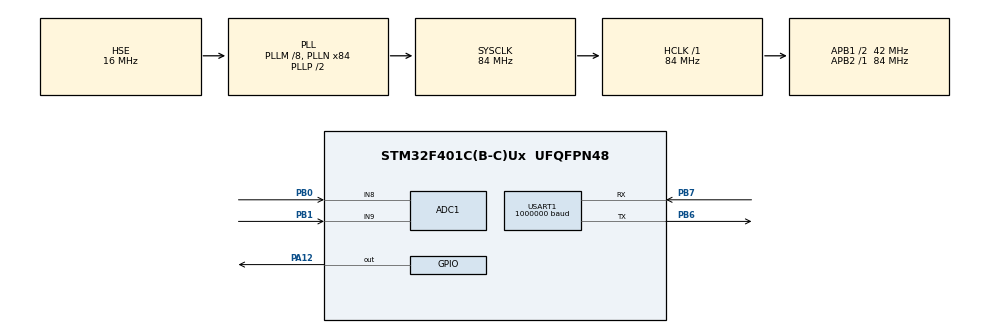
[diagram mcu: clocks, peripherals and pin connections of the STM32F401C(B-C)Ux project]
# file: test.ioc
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ADC1.Channel-0\#ChannelRegularConversion=ADC_CHANNEL_8
ADC1.Channel-1\#ChannelRegularConversion=ADC_CHANNEL_9
ADC1.ContinuousConvMode=ENABLE
ADC1.DMAContinuousRequests=ENABLE
ADC1.NbrOfConversion=2
ADC1.NbrOfConversionFlag=1
ADC1.Rank-0\#ChannelRegularConversion=1
ADC1.Rank-1\#ChannelRegularConversion=2
ADC1.SamplingTime-0\#ChannelRegularConversion=ADC_SAMPLETIME_56CYCLES
ADC1.SamplingTime-1\#ChannelRegularConversion=ADC_SAMPLETIME_56CYCLES
ADC1.ScanConvMode=ENABLE
ADC1.master=1
Dma.ADC1.2.Direction=DMA_PERIPH_TO_MEMORY
Dma.ADC1.2.FIFOMode=DMA_FIFOMODE_ENABLE
Dma.ADC1.2.FIFOThreshold=DMA_FIFO_THRESHOLD_FULL
Dma.ADC1.2.Instance=DMA2_Stream0
Dma.ADC1.2.MemBurst=DMA_MBURST_SINGLE
Dma.ADC1.2.MemDataAlignment=DMA_MDATAALIGN_HALFWORD
Dma.ADC1.2.MemInc=DMA_MINC_ENABLE
Dma.ADC1.2.Mode=DMA_CIRCULAR
Dma.ADC1.2.PeriphBurst=DMA_PBURST_SINGLE
Dma.ADC1.2.PeriphDataAlignment=DMA_PDATAALIGN_HALFWORD
Dma.ADC1.2.PeriphInc=DMA_PINC_DISABLE
Dma.ADC1.2.Priority=DMA_PRIORITY_LOW
Dma.Request0=USART1_RX
Dma.Request1=USART1_TX
Dma.Request2=ADC1
Dma.USART1_RX.0.Direction=DMA_PERIPH_TO_MEMORY
Dma.USART1_RX.0.FIFOMode=DMA_FIFOMODE_ENABLE
Dma.USART1_RX.0.FIFOThreshold=DMA_FIFO_THRESHOLD_FULL
Dma.USART1_RX.0.Instance=DMA2_Stream2
Dma.USART1_RX.0.MemBurst=DMA_MBURST_SINGLE
Dma.USART1_RX.0.MemDataAlignment=DMA_MDATAALIGN_BYTE
Dma.USART1_RX.0.MemInc=DMA_MINC_ENABLE
Dma.USART1_RX.0.Mode=DMA_NORMAL
Dma.USART1_RX.0.PeriphBurst=DMA_PBURST_SINGLE
Dma.USART1_RX.0.PeriphDataAlignment=DMA_PDATAALIGN_BYTE
Dma.USART1_RX.0.PeriphInc=DMA_PINC_DISABLE
Dma.USART1_RX.0.Priority=DMA_PRIORITY_LOW
Dma.USART1_TX.1.Direction=DMA_MEMORY_TO_PERIPH
Dma.USART1_TX.1.FIFOMode=DMA_FIFOMODE_ENABLE
Dma.USART1_TX.1.FIFOThreshold=DMA_FIFO_THRESHOLD_FULL
Dma.USART1_TX.1.Instance=DMA2_Stream7
Dma.USART1_TX.1.MemBurst=DMA_MBURST_SINGLE
Dma.USART1_TX.1.MemDataAlignment=DMA_MDATAALIGN_BYTE
Dma.USART1_TX.1.MemInc=DMA_MINC_ENABLE
Dma.USART1_TX.1.Mode=DMA_NORMAL
Dma.USART1_TX.1.PeriphBurst=DMA_PBURST_SINGLE
Dma.USART1_TX.1.PeriphDataAlignment=DMA_PDATAALIGN_BYTE
Dma.USART1_TX.1.PeriphInc=DMA_PINC_DISABLE
Dma.USART1_TX.1.Priority=DMA_PRIORITY_LOW
Mcu.Family=STM32F4
Mcu.Name=STM32F401C(B-C)Ux
Mcu.Package=UFQFPN48
NVIC.ADC_IRQn=true\:0\:0\:false\:false\:true\:true\:true\:true
NVIC.DMA2_Stream0_IRQn=true\:0\:0\:false\:false\:true\:false\:true\:true
NVIC.DMA2_Stream2_IRQn=true\:0\:0\:false\:false\:true\:false\:true\:true
NVIC.DMA2_Stream7_IRQn=true\:0\:0\:false\:false\:true\:false\:true\:true
NVIC.PriorityGroup=NVIC_PRIORITYGROUP_4
NVIC.TIM2_IRQn=true\:0\:0\:true\:false\:true\:true\:true\:true
NVIC.TIM5_IRQn=true\:0\:0\:true\:false\:true\:true\:true\:true
NVIC.USART1_IRQn=true\:0\:0\:false\:false\:true\:true\:true\:true
PA12.Signal=GPIO_Output
PA13.Mode=Serial_Wire
PA13.Signal=SYS_JTMS-SWDIO
PA14.Mode=Serial_Wire
PA14.Signal=SYS_JTCK-SWCLK
PB0.Signal=ADCx_IN8
PB1.Signal=ADCx_IN9
PB6.Mode=Asynchronous
PB6.Signal=USART1_TX
PB7.Mode=Asynchronous
PB7.Signal=USART1_RX
PH0\ -\ OSC_IN.Mode=HSE-External-Oscillator
PH0\ -\ OSC_IN.Signal=RCC_OSC_IN
PH1\ -\ OSC_OUT.Mode=HSE-External-Oscillator
PH1\ -\ OSC_OUT.Signal=RCC_OSC_OUT
ProjectManager.HeapSize=0x2000
ProjectManager.StackSize=0x4000
ProjectManager.TargetToolchain=STM32CubeIDE
RCC.48MHZClocksFreq_Value=42000000
RCC.AHBFreq_Value=84000000
RCC.APB1CLKDivider=RCC_HCLK_DIV2
RCC.APB1Freq_Value=42000000
RCC.APB1TimFreq_Value=84000000
RCC.APB2Freq_Value=84000000
RCC.APB2TimFreq_Value=84000000
RCC.CortexFreq_Value=84000000
RCC.HCLKFreq_Value=84000000
RCC.HSE_VALUE=16000000
RCC.HSI_VALUE=16000000
RCC.LSE_VALUE=32768
RCC.PLLM=8
RCC.PLLN=84
RCC.PLLSourceVirtual=RCC_PLLSOURCE_HSE
RCC.SYSCLKFreq_VALUE=84000000
RCC.SYSCLKSource=RCC_SYSCLKSOURCE_PLLCLK
RCC.VCOOutputFreq_Value=168000000
SH.ADCx_IN8.0=ADC1_IN8,IN8
SH.ADCx_IN9.0=ADC1_IN9,IN9
STMicroelectronics.X-CUBE-ALGOBUILD.1.4.0.LibraryCcDSPOoLibraryJjDSPOoLibrary=true
TIM2.Period=99
TIM2.Prescaler=83
TIM5.Period=999
TIM5.Prescaler=83
USART1.BaudRate=1000000
USART1.VirtualMode=VM_ASYNC
VP_STMicroelectronics.X-CUBE-ALGOBUILD_VS_DSPOoLibraryJjLibrary_1.4.0_1.4.0.Mode=DSPOoLibraryJjLibrary
VP_TIM2_VS_ClockSourceINT.Mode=Internal
VP_TIM5_VS_ClockSourceINT.Mode=Internal
board=custom

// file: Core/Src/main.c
/* USER CODE BEGIN Header */
/**
  ******************************************************************************
  * @file           : main.c
  * @brief          : Main program body
  ******************************************************************************
  * @attention
  *
  * Copyright (c) 2024 STMicroelectronics.
  * All rights reserved.
  *
  * This software is licensed under terms that can be found in the LICENSE file
  * in the root directory of this software component.
  * If no LICENSE file comes with this software, it is provided AS-IS.
  *
  ******************************************************************************
  */
/* USER CODE END Header */
#include "main.h"
#include "adc.h"
#include "dma.h"
#include "tim.h"
#include "usart.h"
#include "gpio.h"

/* USER CODE BEGIN Includes */

#include "3_Task/tsk_config_and_callback.h"

/* USER CODE END Includes */

void SystemClock_Config(void);

int main(void)
{

  /* MCU Configuration--------------------------------------------------------*/

  /* Reset of all peripherals, Initializes the Flash interface and the Systick. */
  HAL_Init();

  /* Configure the system clock */
  SystemClock_Config();

  /* Initialize all configured peripherals */
  MX_GPIO_Init();
  MX_DMA_Init();
  MX_USART1_UART_Init();
  MX_ADC1_Init();
  MX_TIM2_Init();
  MX_TIM5_Init();
  /* USER CODE BEGIN 2 */

    Task_Init();

  /* USER CODE END 2 */

  /* Infinite loop */
  /* USER CODE BEGIN WHILE */
  while (1)
  {
      Task_Loop();
    /* USER CODE END WHILE */

  }
}

void SystemClock_Config(void)
{
  RCC_OscInitTypeDef RCC_OscInitStruct = {0};
  RCC_ClkInitTypeDef RCC_ClkInitStruct = {0};

  /** Configure the main internal regulator output voltage
  */
  __HAL_RCC_PWR_CLK_ENABLE();
  __HAL_PWR_VOLTAGESCALING_CONFIG(PWR_REGULATOR_VOLTAGE_SCALE2);

  /** Initializes the RCC Oscillators according to the specified parameters
  * in the RCC_OscInitTypeDef structure.
  */
  RCC_OscInitStruct.OscillatorType = RCC_OSCILLATORTYPE_HSE;
  RCC_OscInitStruct.HSEState = RCC_HSE_ON;
  RCC_OscInitStruct.PLL.PLLState = RCC_PLL_ON;
  RCC_OscInitStruct.PLL.PLLSource = RCC_PLLSOURCE_HSE;
  RCC_OscInitStruct.PLL.PLLM = 8;
  RCC_OscInitStruct.PLL.PLLN = 84;
  RCC_OscInitStruct.PLL.PLLP = RCC_PLLP_DIV2;
  RCC_OscInitStruct.PLL.PLLQ = 4;
  if (HAL_RCC_OscConfig(&RCC_OscInitStruct) != HAL_OK)
  {
    Error_Handler();
  }

  /** Initializes the CPU, AHB and APB buses clocks
  */
  RCC_ClkInitStruct.ClockType = RCC_CLOCKTYPE_HCLK|RCC_CLOCKTYPE_SYSCLK
                              |RCC_CLOCKTYPE_PCLK1|RCC_CLOCKTYPE_PCLK2;
  RCC_ClkInitStruct.SYSCLKSource = RCC_SYSCLKSOURCE_PLLCLK;
  RCC_ClkInitStruct.AHBCLKDivider = RCC_SYSCLK_DIV1;
  RCC_ClkInitStruct.APB1CLKDivider = RCC_HCLK_DIV2;
  RCC_ClkInitStruct.APB2CLKDivider = RCC_HCLK_DIV1;

  if (HAL_RCC_ClockConfig(&RCC_ClkInitStruct, FLASH_LATENCY_2) != HAL_OK)
  {
    Error_Handler();
  }
}

void Error_Handler(void)
{
  __disable_irq();
  while (1)
  {
  }
}
